AUTOSAR XML (schema 4-3-0)
package /Impl_SWC_DID_ARPkg
  swc implementation Impl_SWC_DID_type: programming-language=C, sw-version=1.0.0, vendor-id=0, behavior=SWC_DID_type_IB
    code-descriptors:
      code SRC: artifact-descriptors=autosar-engineering-object={short-label=EngObject, category=SWSRC}
    resource consumption ResourceConsumption
      memory section Mem_SWC_DID_CODE: size=0, sw-addrmethod=CODE, symbol=CODE
package /Interface_DID_ARPkg
  client server interface IF_DIDReadCDD
    4 x operation:
      CSOP_DIDGet_DKCKey
        4 x arg, all with server-argument-impl-policy=USE-ARGUMENT-TYPE:
          u8Array8_DKCKey: type=u8Array8_DKCKey_type, direction=OUT
          u8_DIDSta_DKCKey: type=uint8, direction=OUT
          u16_DIDNum_DKCKey: type=uint16, direction=IN
          u16_DIDLen_DKCKey: type=uint16, direction=IN
      CSOP_DIDGet_FoxPiDrivingCtrl
        4 x arg, all with server-argument-impl-policy=USE-ARGUMENT-TYPE:
          u8Array21_FoxPiDrivingCtrl: type=u8Array21_FoxPiDrivingCtrl_type, direction=OUT
          u8_DIDSta_FoxPiDrivingCtrl: type=uint8, direction=OUT
          u16_DIDNum_FoxPiDrivingCtrl: type=uint16, direction=IN
          u16_DIDLen_FoxPiDrivingCtrl: type=uint16, direction=IN
      CSOP_DIDGet_FoxPiLampCtrl
        4 x arg, all with server-argument-impl-policy=USE-ARGUMENT-TYPE:
          u8Array6_FoxPiLampCtrl: type=u8Array6_FoxPiLampCtrl_type, direction=OUT
          u8_DIDSta_FoxPiLampCtrl: type=uint8, direction=OUT
          u16_DIDNum_FoxPiLampCtrl: type=uint16, direction=IN
          u16_DIDLen_FoxPiLampCtrl: type=uint16, direction=IN
      CSOP_DIDGet_FoxPiCtrlEnSw
        4 x arg, all with server-argument-impl-policy=USE-ARGUMENT-TYPE:
          u8_FoxPiCtrlEnSw: type=uint8, direction=OUT
          u8_DIDSta_FoxPiCtrlEnSw: type=uint8, direction=OUT
          u16_DIDNum_FoxPiCtrlEnSw: type=uint16, direction=IN
          u16_DIDLen_FoxPiCtrlEnSw: type=uint16, direction=IN
  client server interface IF_DIDWriteCDD
    19 x operation:
      CSOP_DIDSet_DKCKey
        arg u16_DIDNum_DKCKey: type=uint16, direction=IN, server-argument-impl-policy=USE-ARGUMENT-TYPE
        arg u16_DIDLen_DKCKey: type=uint16, direction=IN, server-argument-impl-policy=USE-ARGUMENT-TYPE
        arg u8Array8_DKCKey: type=u8Array8_DKCKey_type, direction=IN, server-argument-impl-policy=USE-ARGUMENT-TYPE
      CSOP_DIDSet_FoxPiDrivingCtrl
        arg u16_DIDNum_FoxPiDrivingCtrl: type=uint16, direction=IN, server-argument-impl-policy=USE-ARGUMENT-TYPE
        arg u16_DIDLen_FoxPiDrivingCtrl: type=uint16, direction=IN, server-argument-impl-policy=USE-ARGUMENT-TYPE
        arg u8Array21_FoxPiDrivingCtrl: type=u8Array21_FoxPiDrivingCtrl_type, direction=IN, server-argument-impl-policy=USE-ARGUMENT-TYPE
      CSOP_DIDSet_FoxPiMotionSta
        arg u16_DIDNum_FoxPiMotionSta: type=uint16, direction=IN, server-argument-impl-policy=USE-ARGUMENT-TYPE
        arg u16_DIDLen_FoxPiMotionSta: type=uint16, direction=IN, server-argument-impl-policy=USE-ARGUMENT-TYPE
        arg u8Array13_FoxPiMotionSta: type=u8Array13_FoxPiMotionSta_type, direction=IN, server-argument-impl-policy=USE-ARGUMENT-TYPE
      CSOP_DIDSet_FoxPiBrakeSta
        arg u16_DIDNum_FoxPiBrakeSta: type=uint16, direction=IN, server-argument-impl-policy=USE-ARGUMENT-TYPE
        arg u16_DIDLen_FoxPiBrakeSta: type=uint16, direction=IN, server-argument-impl-policy=USE-ARGUMENT-TYPE
        arg u8Array13_FoxPiBrakeSta: type=u8Array13_FoxPiBrakeSta_type, direction=IN, server-argument-impl-policy=USE-ARGUMENT-TYPE
      CSOP_DIDSet_FoxPiWheelSpd
        arg u16_DIDNum_FoxPiWheelSpd: type=uint16, direction=IN, server-argument-impl-policy=USE-ARGUMENT-TYPE
        arg u16_DIDLen_FoxPiWheelSpd: type=uint16, direction=IN, server-argument-impl-policy=USE-ARGUMENT-TYPE
        arg u8Array16_FoxPiWheelSpd: type=u8Array16_FoxPiWheelSpd_type, direction=IN, server-argument-impl-policy=USE-ARGUMENT-TYPE
      CSOP_DIDSet_FoxPiEPSSta
        arg u16_DIDNum_FoxPiEPSSta: type=uint16, direction=IN, server-argument-impl-policy=USE-ARGUMENT-TYPE
        arg u16_DIDLen_FoxPiEPSSta: type=uint16, direction=IN, server-argument-impl-policy=USE-ARGUMENT-TYPE
        arg u8Array11_FoxPiEPSSta: type=u8Array11_FoxPiEPSSta_type, direction=IN, server-argument-impl-policy=USE-ARGUMENT-TYPE
      CSOP_DIDSet_FoxPiButtonSta
        arg u16_DIDNum_FoxPiButtonSta: type=uint16, direction=IN, server-argument-impl-policy=USE-ARGUMENT-TYPE
        arg u16_DIDLen_FoxPiButtonSta: type=uint16, direction=IN, server-argument-impl-policy=USE-ARGUMENT-TYPE
        arg u8Array2_FoxPiButtonSta: type=u8Array2_FoxPiButtonSta_type, direction=IN, server-argument-impl-policy=USE-ARGUMENT-TYPE
      CSOP_DIDSet_FoxPiUSSDist
        arg u16_DIDNum_FoxPiUSSDist: type=uint16, direction=IN, server-argument-impl-policy=USE-ARGUMENT-TYPE
        arg u16_DIDLen_FoxPiUSSDist: type=uint16, direction=IN, server-argument-impl-policy=USE-ARGUMENT-TYPE
        arg u8Array20_FoxPiUSSDist: type=u8Array20_FoxPiUSSDist_type, direction=IN, server-argument-impl-policy=USE-ARGUMENT-TYPE
      CSOP_DIDSet_FoxPiUSSFaultSta
        arg u16_DIDNum_FoxPiUSSFaultSta: type=uint16, direction=IN, server-argument-impl-policy=USE-ARGUMENT-TYPE
        arg u16_DIDLen_FoxPiUSSFaultSta: type=uint16, direction=IN, server-argument-impl-policy=USE-ARGUMENT-TYPE
        arg u8Array2_FoxPiUSSFaultSta: type=u8Array2_FoxPiUSSFaultSta_type, direction=IN, server-argument-impl-policy=USE-ARGUMENT-TYPE
      CSOP_DIDSet_FoxPiPTGUSSSw
        arg u16_DIDNum_FoxPiPTGUSSSw: type=uint16, direction=IN, server-argument-impl-policy=USE-ARGUMENT-TYPE
        arg u16_DIDLen_FoxPiPTGUSSSw: type=uint16, direction=IN, server-argument-impl-policy=USE-ARGUMENT-TYPE
        arg u8_FoxPiPTGUSSSw: type=uint8, direction=IN, server-argument-impl-policy=USE-ARGUMENT-TYPE
      CSOP_DIDSet_FoxPiSwSta
        arg u16_DIDNum_FoxPiSwSta: type=uint16, direction=IN, server-argument-impl-policy=USE-ARGUMENT-TYPE
        arg u16_DIDLen_FoxPiSwSta: type=uint16, direction=IN, server-argument-impl-policy=USE-ARGUMENT-TYPE
        arg u8Array2_FoxPiSwSta: type=u8Array2_FoxPiSwSta_type, direction=IN, server-argument-impl-policy=USE-ARGUMENT-TYPE
      CSOP_DIDSet_FoxPiLampSta
        arg u16_DIDNum_FoxPiLampSta: type=uint16, direction=IN, server-argument-impl-policy=USE-ARGUMENT-TYPE
        arg u16_DIDLen_FoxPiLampSta: type=uint16, direction=IN, server-argument-impl-policy=USE-ARGUMENT-TYPE
        arg u8Array2_FoxPiLampSta: type=u8Array2_FoxPiLampSta_type, direction=IN, server-argument-impl-policy=USE-ARGUMENT-TYPE
      CSOP_DIDSet_FoxPiLampCtrl
        arg u16_DIDNum_FoxPiLampCtrl: type=uint16, direction=IN, server-argument-impl-policy=USE-ARGUMENT-TYPE
        arg u16_DIDLen_FoxPiLampCtrl: type=uint16, direction=IN, server-argument-impl-policy=USE-ARGUMENT-TYPE
        arg u8Array6_FoxPiLampCtrl: type=u8Array6_FoxPiLampCtrl_type, direction=IN, server-argument-impl-policy=USE-ARGUMENT-TYPE
      CSOP_DIDSet_FoxPiBattSta
        arg u16_DIDNum_FoxPiBattSta: type=uint16, direction=IN, server-argument-impl-policy=USE-ARGUMENT-TYPE
        arg u16_DIDLen_FoxPiBattSta: type=uint16, direction=IN, server-argument-impl-policy=USE-ARGUMENT-TYPE
        arg u8Array4_FoxPiBattSta: type=u8Array4_FoxPiBattSta_type, direction=IN, server-argument-impl-policy=USE-ARGUMENT-TYPE
      CSOP_DIDSet_FoxPiTPMSSta
        arg u16_DIDNum_FoxPiTPMSSta: type=uint16, direction=IN, server-argument-impl-policy=USE-ARGUMENT-TYPE
        arg u16_DIDLen_FoxPiTPMSSta: type=uint16, direction=IN, server-argument-impl-policy=USE-ARGUMENT-TYPE
        arg u8Array13_FoxPiTPMSSta: type=u8Array13_FoxPiTPMSSta_type, direction=IN, server-argument-impl-policy=USE-ARGUMENT-TYPE
      CSOP_DIDSet_FoxPiPedalPos
        arg u16_DIDNum_FoxPiPedalPos: type=uint16, direction=IN, server-argument-impl-policy=USE-ARGUMENT-TYPE
        arg u16_DIDLen_FoxPiPedalPos: type=uint16, direction=IN, server-argument-impl-policy=USE-ARGUMENT-TYPE
        arg u8Array3_FoxPiPedalPos: type=u8Array3_FoxPiPedalPos_type, direction=IN, server-argument-impl-policy=USE-ARGUMENT-TYPE
      CSOP_DIDSet_FoxPiMotorSta
        arg u16_DIDNum_FoxPiMotorSta: type=uint16, direction=IN, server-argument-impl-policy=USE-ARGUMENT-TYPE
        arg u16_DIDLen_FoxPiMotorSta: type=uint16, direction=IN, server-argument-impl-policy=USE-ARGUMENT-TYPE
        arg u8Array11_FoxPiMotorSta: type=u8Array11_FoxPiMotorSta_type, direction=IN, server-argument-impl-policy=USE-ARGUMENT-TYPE
      CSOP_DIDSet_FoxPiShifterAllow
        arg u16_DIDNum_FoxPiShifterAllow: type=uint16, direction=IN, server-argument-impl-policy=USE-ARGUMENT-TYPE
        arg u16_DIDLen_FoxPiShifterAllow: type=uint16, direction=IN, server-argument-impl-policy=USE-ARGUMENT-TYPE
        arg u8Array3_FoxPiShifterAllow: type=u8Array3_FoxPiShifterAllow_type, direction=IN, server-argument-impl-policy=USE-ARGUMENT-TYPE
      CSOP_DIDSet_FoxPiCtrlEnSw
        arg u16_DIDNum_FoxPiCtrlEnSw: type=uint16, direction=IN, server-argument-impl-policy=USE-ARGUMENT-TYPE
        arg u16_DIDLen_FoxPiCtrlEnSw: type=uint16, direction=IN, server-argument-impl-policy=USE-ARGUMENT-TYPE
        arg u8_FoxPiCtrlEnSw: type=uint8, direction=IN, server-argument-impl-policy=USE-ARGUMENT-TYPE
package /SWC_DID_ARPkg
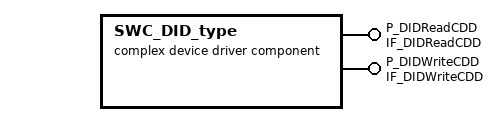
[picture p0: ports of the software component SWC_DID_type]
  complex device driver sw component type SWC_DID_type
    provide port P_DIDReadCDD: provided-interface=IF_DIDReadCDD
    provide port P_DIDWriteCDD: provided-interface=IF_DIDWriteCDD
    behavior SWC_DID_type_IB: handle-termination-and-restart=NO-SUPPORT
      23 x operation invoked event:
        oie_P_DIDReadCDD_CSOP_DIDGet_DKCKey: start-on-event=run_DIDGet_DKCKey, operation=P_DIDReadCDD.CSOP_DIDGet_DKCKey
        oie_P_DIDWriteCDD_CSOP_DIDSet_DKCKey: start-on-event=run_DIDSet_DKCKey, operation=P_DIDWriteCDD.CSOP_DIDSet_DKCKey
        oie_P_DIDReadCDD_CSOP_DIDGet_FoxPiDrivingCtrl: start-on-event=run_DIDGet_FoxPiDrivingCtrl, operation=P_DIDReadCDD.CSOP_DIDGet_FoxPiDrivingCtrl
        oie_P_DIDWriteCDD_CSOP_DIDSet_FoxPiDrivingCtrl: start-on-event=run_DIDSet_FoxPiDrivingCtrl, operation=P_DIDWriteCDD.CSOP_DIDSet_FoxPiDrivingCtrl
        oie_P_DIDWriteCDD_CSOP_DIDSet_FoxPiMotionSta: start-on-event=run_DIDSet_FoxPiMotionSta, operation=P_DIDWriteCDD.CSOP_DIDSet_FoxPiMotionSta
        oie_P_DIDWriteCDD_CSOP_DIDSet_FoxPiBrakeSta: start-on-event=run_DIDSet_FoxPiBrakeSta, operation=P_DIDWriteCDD.CSOP_DIDSet_FoxPiBrakeSta
        oie_P_DIDWriteCDD_CSOP_DIDSet_FoxPiWheelSpd: start-on-event=run_DIDSet_FoxPiWheelSpd, operation=P_DIDWriteCDD.CSOP_DIDSet_FoxPiWheelSpd
        oie_P_DIDWriteCDD_CSOP_DIDSet_FoxPiEPSSta: start-on-event=run_DIDSet_FoxPiEPSSta, operation=P_DIDWriteCDD.CSOP_DIDSet_FoxPiEPSSta
        oie_P_DIDWriteCDD_CSOP_DIDSet_FoxPiButtonSta: start-on-event=run_DIDSet_FoxPiButtonSta, operation=P_DIDWriteCDD.CSOP_DIDSet_FoxPiButtonSta
        oie_P_DIDWriteCDD_CSOP_DIDSet_FoxPiUSSDist: start-on-event=run_DIDSet_FoxPiUSSDist, operation=P_DIDWriteCDD.CSOP_DIDSet_FoxPiUSSDist
        oie_P_DIDWriteCDD_CSOP_DIDSet_FoxPiUSSFaultSta: start-on-event=run_DIDSet_FoxPiUSSFaultSta, operation=P_DIDWriteCDD.CSOP_DIDSet_FoxPiUSSFaultSta
        oie_P_DIDWriteCDD_CSOP_DIDSet_FoxPiPTGUSSSw: start-on-event=run_DIDSet_FoxPiPTGUSSSw, operation=P_DIDWriteCDD.CSOP_DIDSet_FoxPiPTGUSSSw
        oie_P_DIDWriteCDD_CSOP_DIDSet_FoxPiSwSta: start-on-event=run_DIDSet_FoxPiSwSta, operation=P_DIDWriteCDD.CSOP_DIDSet_FoxPiSwSta
        oie_P_DIDWriteCDD_CSOP_DIDSet_FoxPiLampSta: start-on-event=run_DIDSet_FoxPiLampSta, operation=P_DIDWriteCDD.CSOP_DIDSet_FoxPiLampSta
        oie_P_DIDReadCDD_CSOP_DIDGet_FoxPiLampCtrl: start-on-event=run_DIDGet_FoxPiLampCtrl, operation=P_DIDReadCDD.CSOP_DIDGet_FoxPiLampCtrl
        oie_P_DIDWriteCDD_CSOP_DIDSet_FoxPiLampCtrl: start-on-event=run_DIDSet_FoxPiLampCtrl, operation=P_DIDWriteCDD.CSOP_DIDSet_FoxPiLampCtrl
        oie_P_DIDWriteCDD_CSOP_DIDSet_FoxPiBattSta: start-on-event=run_DIDSet_FoxPiBattSta, operation=P_DIDWriteCDD.CSOP_DIDSet_FoxPiBattSta
        oie_P_DIDWriteCDD_CSOP_DIDSet_FoxPiTPMSSta: start-on-event=run_DIDSet_FoxPiTPMSSta, operation=P_DIDWriteCDD.CSOP_DIDSet_FoxPiTPMSSta
        oie_P_DIDWriteCDD_CSOP_DIDSet_FoxPiPedalPos: start-on-event=run_DIDSet_FoxPiPedalPos, operation=P_DIDWriteCDD.CSOP_DIDSet_FoxPiPedalPos
        oie_P_DIDWriteCDD_CSOP_DIDSet_FoxPiMotorSta: start-on-event=run_DIDSet_FoxPiMotorSta, operation=P_DIDWriteCDD.CSOP_DIDSet_FoxPiMotorSta
        oie_P_DIDWriteCDD_CSOP_DIDSet_FoxPiShifterAllow: start-on-event=run_DIDSet_FoxPiShifterAllow, operation=P_DIDWriteCDD.CSOP_DIDSet_FoxPiShifterAllow
        oie_P_DIDReadCDD_CSOP_DIDGet_FoxPiCtrlEnSw: start-on-event=run_DIDGet_FoxPiCtrlEnSw, operation=P_DIDReadCDD.CSOP_DIDGet_FoxPiCtrlEnSw
        oie_P_DIDWriteCDD_CSOP_DIDSet_FoxPiCtrlEnSw: start-on-event=run_DIDSet_FoxPiCtrlEnSw, operation=P_DIDWriteCDD.CSOP_DIDSet_FoxPiCtrlEnSw
      port-api-options:
        enable-take-address=false, indirect-api=false, port=P_DIDWriteCDD
        enable-take-address=false, indirect-api=false, port=P_DIDReadCDD
      23 x runnable:
        run_DIDGet_DKCKey
        run_DIDSet_DKCKey
        run_DIDGet_FoxPiDrivingCtrl
        run_DIDSet_FoxPiDrivingCtrl
        run_DIDSet_FoxPiMotionSta
        run_DIDSet_FoxPiBrakeSta
        run_DIDSet_FoxPiWheelSpd
        run_DIDSet_FoxPiEPSSta
        run_DIDSet_FoxPiButtonSta
        run_DIDSet_FoxPiUSSDist
        run_DIDSet_FoxPiUSSFaultSta
        run_DIDSet_FoxPiPTGUSSSw
        run_DIDSet_FoxPiSwSta
        run_DIDSet_FoxPiLampSta
        run_DIDGet_FoxPiLampCtrl
        run_DIDSet_FoxPiLampCtrl
        run_DIDSet_FoxPiBattSta
        run_DIDSet_FoxPiTPMSSta
        run_DIDSet_FoxPiPedalPos
        run_DIDSet_FoxPiMotorSta
        run_DIDSet_FoxPiShifterAllow
        run_DIDGet_FoxPiCtrlEnSw
        run_DIDSet_FoxPiCtrlEnSw
package /TypeDef_DID_ARPkg
  17 x impl type, all with category=ARRAY:
    u8Array8_DKCKey_type
      element u8_Element: category=VALUE, array-size=8, array-size-semantics=FIXED-SIZE, base-type=uint8
    u8Array21_FoxPiDrivingCtrl_type
      element u8_Element: category=VALUE, array-size=21, array-size-semantics=FIXED-SIZE, base-type=uint8
    u8Array13_FoxPiMotionSta_type
      element u8_Element: category=VALUE, array-size=13, array-size-semantics=FIXED-SIZE, base-type=uint8
    u8Array13_FoxPiBrakeSta_type
      element u8_Element: category=VALUE, array-size=13, array-size-semantics=FIXED-SIZE, base-type=uint8
    u8Array16_FoxPiWheelSpd_type
      element u8_Element: category=VALUE, array-size=16, array-size-semantics=FIXED-SIZE, base-type=uint8
    u8Array11_FoxPiEPSSta_type
      element u8_Element: category=VALUE, array-size=11, array-size-semantics=FIXED-SIZE, base-type=uint8
    u8Array2_FoxPiButtonSta_type
      element u8_Element: category=VALUE, array-size=2, array-size-semantics=FIXED-SIZE, base-type=uint8
    u8Array20_FoxPiUSSDist_type
      element u8_Element: category=VALUE, array-size=20, array-size-semantics=FIXED-SIZE, base-type=uint8
    u8Array2_FoxPiUSSFaultSta_type
      element u8_Element: category=VALUE, array-size=2, array-size-semantics=FIXED-SIZE, base-type=uint8
    u8Array2_FoxPiSwSta_type
      element u8_Element: category=VALUE, array-size=2, array-size-semantics=FIXED-SIZE, base-type=uint8
    u8Array2_FoxPiLampSta_type
      element u8_Element: category=VALUE, array-size=2, array-size-semantics=FIXED-SIZE, base-type=uint8
    u8Array6_FoxPiLampCtrl_type
      element u8_Element: category=VALUE, array-size=6, array-size-semantics=FIXED-SIZE, base-type=uint8
    u8Array4_FoxPiBattSta_type
      element u8_Element: category=VALUE, array-size=4, array-size-semantics=FIXED-SIZE, base-type=uint8
    u8Array13_FoxPiTPMSSta_type
      element u8_Element: category=VALUE, array-size=13, array-size-semantics=FIXED-SIZE, base-type=uint8
    u8Array3_FoxPiPedalPos_type
      element u8_Element: category=VALUE, array-size=3, array-size-semantics=FIXED-SIZE, base-type=uint8
    u8Array11_FoxPiMotorSta_type
      element u8_Element: category=VALUE, array-size=11, array-size-semantics=FIXED-SIZE, base-type=uint8
    u8Array3_FoxPiShifterAllow_type
      element u8_Element: category=VALUE, array-size=3, array-size-semantics=FIXED-SIZE, base-type=uint8
